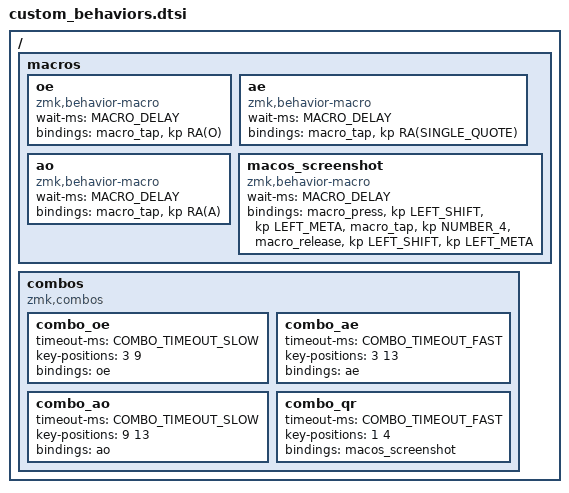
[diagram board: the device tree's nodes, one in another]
/*                                      36 KEY MATRIX / LAYOUT MAPPING

  ╭────────────────────┬─────────────────────╮
  │  1   2   3   4   5 │  6   7   8   9  10  │
  │ 13  14  15  16  17 │ 18  19  20  21  22  │
  │ 25  26  27  28  29 │ 30  31  32  33  34  │
  ╰───────╮ 36  37  38 │ 39  40  41 ╭────────╯
          ╰────────────┴────────────╯               */

#define COMBO_TIMEOUT_FAST 30
#define COMBO_TIMEOUT_SLOW 40
#define MACRO_DELAY 40


/ {
    macros {
        oe: oe {
            compatible = "zmk,behavior-macro";
            #binding-cells = <0>;
            wait-ms = <MACRO_DELAY>;
            bindings = <&macro_tap &kp RA(O)>;
        };

        ae: ae {
            compatible = "zmk,behavior-macro";
            #binding-cells = <0>;
            wait-ms = <MACRO_DELAY>;
            bindings = <&macro_tap &kp RA(SINGLE_QUOTE)>;
        };

        ao: ao {
            compatible = "zmk,behavior-macro";
            #binding-cells = <0>;
            wait-ms = <MACRO_DELAY>;
            bindings = <&macro_tap &kp RA(A)>;
        };

        macos_screenshot: macos_screenshot {
            compatible = "zmk,behavior-macro";
            #binding-cells = <0>;
            wait-ms = <MACRO_DELAY>;
            bindings = <&macro_press &kp LEFT_SHIFT &kp LEFT_META>
              , <&macro_tap &kp NUMBER_4>
              , <&macro_release &kp LEFT_SHIFT &kp LEFT_META>;
        };
    };

    combos {
        compatible = "zmk,combos";

        combo_oe {
            timeout-ms = <COMBO_TIMEOUT_SLOW>;
            key-positions = <3 9>;
            bindings = <&oe>;
        };

        combo_ae {
            timeout-ms = <COMBO_TIMEOUT_FAST>;
            key-positions = <3 13>;
            bindings = <&ae>;
        };

        combo_ao {
            timeout-ms = <COMBO_TIMEOUT_SLOW>;
            key-positions = <9 13>;
            bindings = <&ao>;
        };

        combo_qr {
            timeout-ms = <COMBO_TIMEOUT_FAST>;
            key-positions = <1 4>;
            bindings = <&macos_screenshot>;
        };
    };
};
